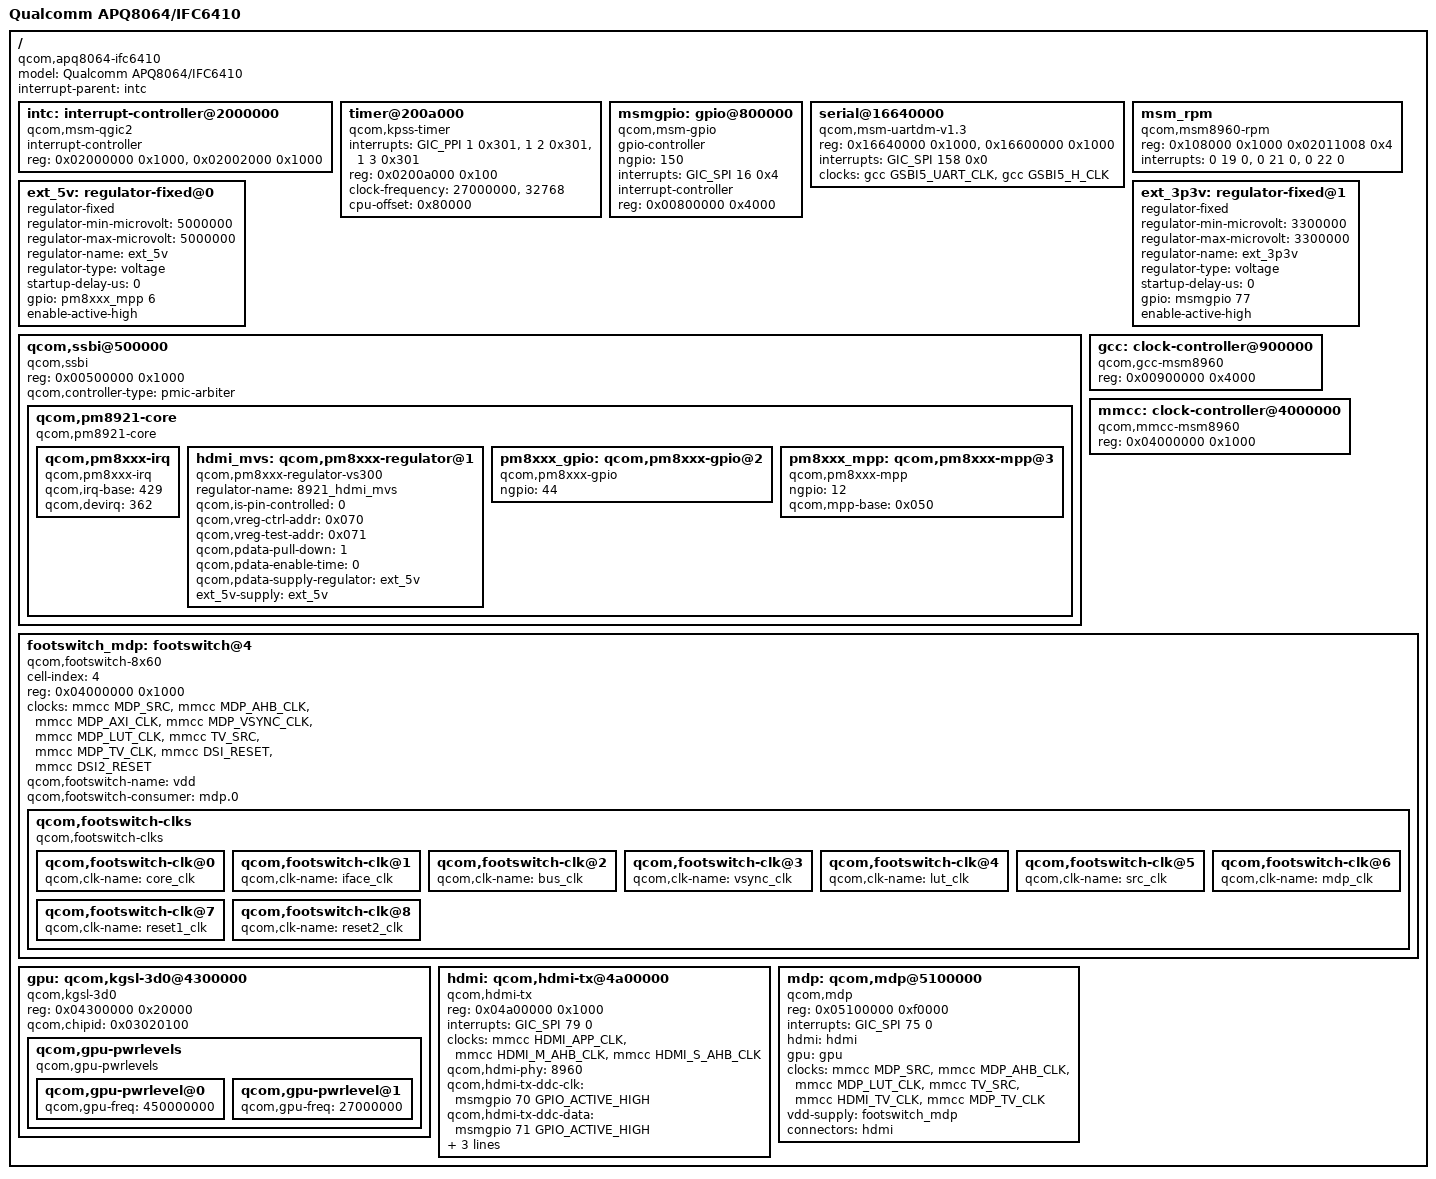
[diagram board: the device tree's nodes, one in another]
/dts-v1/;

/include/ "skeleton.dtsi"

#include <dt-bindings/clock/qcom,gcc-msm8960.h>
#include <dt-bindings/clock/qcom,mmcc-msm8960.h>
#include <dt-bindings/reset/qcom,mmcc-msm8960.h>
#include <dt-bindings/interrupt-controller/arm-gic.h>
#include <dt-bindings/gpio/gpio.h>

/ {
	model = "Qualcomm APQ8064/IFC6410";
	compatible = "qcom,apq8064-ifc6410", "qcom,apq8064";
	interrupt-parent = <&intc>;

	intc: interrupt-controller@2000000 {
		compatible = "qcom,msm-qgic2";
		interrupt-controller;
		#interrupt-cells = <3>;
		reg = < 0x02000000 0x1000 >,
		      < 0x02002000 0x1000 >;
	};

	timer@200a000 {
		compatible = "qcom,kpss-timer", "qcom,msm-timer";
		interrupts = <GIC_PPI 1 0x301>,
			     <1 2 0x301>,
			     <1 3 0x301>;
		reg = <0x0200a000 0x100>;
		clock-frequency = <27000000>,
				  <32768>;
		cpu-offset = <0x80000>;
	};

	msmgpio: gpio@800000 {
		compatible = "qcom,msm-gpio";
		gpio-controller;
		#gpio-cells = <2>;
		ngpio = <150>;
		interrupts = <GIC_SPI 16 0x4>;
		interrupt-controller;
		#interrupt-cells = <2>;
		reg = <0x00800000 0x4000>;
	};

	serial@16640000 {
		compatible = "qcom,msm-uartdm-v1.3", "qcom,msm-uartdm";
		reg = <0x16640000 0x1000>,
		      <0x16600000 0x1000>;
		interrupts = <GIC_SPI 158 0x0>;
		clocks = <&gcc GSBI5_UART_CLK>, <&gcc GSBI5_H_CLK>;
		clock-names = "core", "iface";
	};

	msm_rpm {
		compatible = "qcom,msm8960-rpm";
		reg = <0x108000  0x1000 0x02011008 0x4>;
		interrupts = <0 19 0>, <0 21 0>, <0 22 0>;
		interrupt-names = "ack", "err", "wakeup";
	};

	ext_5v: regulator-fixed@0 {
		compatible = "regulator-fixed";

		regulator-min-microvolt = <5000000>;
		regulator-max-microvolt = <5000000>;

		regulator-name = "ext_5v";
		regulator-type = "voltage";
		startup-delay-us = <0>;

		gpio = <&pm8xxx_mpp 6 GPIO_ACTIVE_HIGH>;

		enable-active-high;
	};

	ext_3p3v: regulator-fixed@1 {
		compatible = "regulator-fixed";

		regulator-min-microvolt = <3300000>;
		regulator-max-microvolt = <3300000>;

		regulator-name = "ext_3p3v";
		regulator-type = "voltage";
		startup-delay-us = <0>;

		gpio = <&msmgpio 77 GPIO_ACTIVE_HIGH>;

		enable-active-high;
	};

	qcom,ssbi@500000 {
		compatible = "qcom,ssbi";
		reg = <0x00500000 0x1000>;
		qcom,controller-type = "pmic-arbiter";

		qcom,pm8921-core {
			compatible = "qcom,pm8921-core";

			qcom,pm8xxx-irq {
				compatible = "qcom,pm8xxx-irq";
				qcom,irq-base = <429>;
				qcom,devirq = <362>;
			};

			hdmi_mvs: qcom,pm8xxx-regulator@1 {
				compatible = "qcom,pm8xxx-regulator-vs300", "qcom,pm8xxx-regulator";
				regulator-name = "8921_hdmi_mvs";
				qcom,is-pin-controlled = <0>;
				qcom,vreg-ctrl-addr = <0x070>;
				qcom,vreg-test-addr = <0x071>;
				qcom,pdata-pull-down = <1>;
				qcom,pdata-enable-time = <0>;
				qcom,pdata-supply-regulator = "ext_5v";
				ext_5v-supply = <&ext_5v>;
			};

			pm8xxx_gpio: qcom,pm8xxx-gpio@2 {
				compatible = "qcom,pm8xxx-gpio";
				#gpio-cells = <2>;
				ngpio = <44>;
			};

			pm8xxx_mpp: qcom,pm8xxx-mpp@3 {
				compatible = "qcom,pm8xxx-mpp";
				#gpio-cells = <2>;
				ngpio = <12>;
				qcom,mpp-base = <0x050>;
			};
		};
	};

	gcc: clock-controller@900000 {
		compatible = "qcom,gcc-msm8960", "qcom,gcc";
		reg = <0x00900000 0x4000>;
		#clock-cells = <1>;
		#reset-cells = <1>;
	};

	mmcc: clock-controller@4000000 {
		compatible = "qcom,mmcc-msm8960", "qcom,mmcc";
		reg = <0x04000000 0x1000>;
		#clock-cells = <1>;
		#reset-cells = <1>;
	};

	footswitch_mdp: footswitch@4 {
		compatible = "qcom,footswitch-8x60";
		cell-index = <4>;
		reg = <0x04000000 0x1000>;
		clock-names =
		    "core_clk",
		    "iface_clk",
		    "bus_clk",
		    "vsync_clk",
		    "lut_clk",
		    "src_clk",
		    "mdp_clk",
		    "reset1_clk",
		    "reset2_clk";
		clocks =
		    <&mmcc MDP_SRC>,
		    <&mmcc MDP_AHB_CLK>,
		    <&mmcc MDP_AXI_CLK>,
		    <&mmcc MDP_VSYNC_CLK>,
		    <&mmcc MDP_LUT_CLK>,
		    <&mmcc TV_SRC>,
		    <&mmcc MDP_TV_CLK>,
		    <&mmcc DSI_RESET>,
		    <&mmcc DSI2_RESET>;
		qcom,footswitch-name = "vdd";
		qcom,footswitch-consumer = "mdp.0";
		qcom,footswitch-clks {
			compatible = "qcom,footswitch-clks";
			qcom,footswitch-clk@0 {
				qcom,clk-name = "core_clk";
			};
			qcom,footswitch-clk@1 {
				qcom,clk-name = "iface_clk";
			};
			qcom,footswitch-clk@2 {
				qcom,clk-name = "bus_clk";
			};
			qcom,footswitch-clk@3 {
				qcom,clk-name = "vsync_clk";
			};
			qcom,footswitch-clk@4 {
				qcom,clk-name = "lut_clk";
			};
			qcom,footswitch-clk@5 {
				qcom,clk-name = "src_clk";
			};
			qcom,footswitch-clk@6 {
				qcom,clk-name = "mdp_clk";
			};
			qcom,footswitch-clk@7 {
				qcom,clk-name = "reset1_clk";
			};
			qcom,footswitch-clk@8 {
				qcom,clk-name = "reset2_clk";
			};
		};
	};

	gpu: qcom,kgsl-3d0@4300000 {
		compatible = "qcom,kgsl-3d0";
		reg = <0x04300000 0x20000>;
		qcom,chipid = <0x03020100>;

		qcom,gpu-pwrlevels {
			compatible = "qcom,gpu-pwrlevels";

			qcom,gpu-pwrlevel@0 {
				qcom,gpu-freq = <450000000>;
			};

			qcom,gpu-pwrlevel@1 {
				qcom,gpu-freq = <27000000>;
			};
		};
	};

	hdmi: qcom,hdmi-tx@4a00000 {
		compatible = "qcom,hdmi-tx";
		reg-names = "core_physical";
		reg = <0x04a00000 0x1000>;
		interrupts = <GIC_SPI 79 0>;
		clock-names =
		    "core_clk",
		    "master_iface_clk",
		    "slave_iface_clk";
		clocks =
		    <&mmcc HDMI_APP_CLK>,
		    <&mmcc HDMI_M_AHB_CLK>,
		    <&mmcc HDMI_S_AHB_CLK>;
		qcom,hdmi-phy = "8960";
		qcom,hdmi-tx-ddc-clk = <&msmgpio 70 GPIO_ACTIVE_HIGH>;
		qcom,hdmi-tx-ddc-data = <&msmgpio 71 GPIO_ACTIVE_HIGH>;
		qcom,hdmi-tx-hpd = <&msmgpio 72 GPIO_ACTIVE_HIGH>;
		core-vdda-supply = <&hdmi_mvs>;
		hdmi-mux-vdd-supply = <&ext_3p3v>;
	};

	mdp: qcom,mdp@5100000 {
		compatible = "qcom,mdp";
		reg = <0x05100000 0xf0000>;
		interrupts = <GIC_SPI 75 0>;
		hdmi = <&hdmi>;
		gpu = <&gpu>;
		clock-names =
		    "core_clk",
		    "iface_clk",
		    "lut_clk",
		    "src_clk",
		    "hdmi_clk",
		    "mdp_clk";
		clocks =
		    <&mmcc MDP_SRC>,
		    <&mmcc MDP_AHB_CLK>,
		    <&mmcc MDP_LUT_CLK>,
		    <&mmcc TV_SRC>,
		    <&mmcc HDMI_TV_CLK>,
		    <&mmcc MDP_TV_CLK>;
		vdd-supply = <&footswitch_mdp>;
		connectors = <&hdmi>;
	};
};
